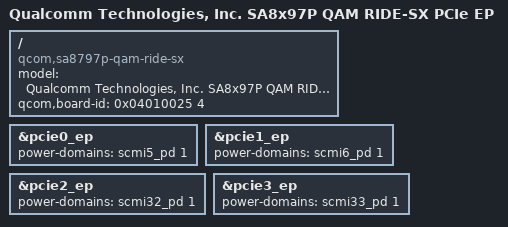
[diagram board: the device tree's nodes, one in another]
// SPDX-License-Identifier: BSD-3-Clause
/*
 * Copyright (c) Qualcomm Technologies, Inc. and/or its subsidiaries.
 */

/dts-v1/;

#include "sa8x97p.dtsi"
#include "sa8797p.dtsi"

/ {
	model = "Qualcomm Technologies, Inc. SA8x97P QAM RIDE-SX PCIe EP";
	compatible = "qcom,sa8797p-qam-ride-sx", "qcom,sa8797p-qam", "qcom,sa8797p";
	qcom,board-id = <0x04010025 4>;
};

&pcie0_ep {
	power-domains = <&scmi5_pd 1>;
	power-domain-names = "power";
	status = "okay";
};

&pcie1_ep {
	power-domains = <&scmi6_pd 1>;
	power-domain-names = "power";
};

&pcie2_ep {
	power-domains = <&scmi32_pd 1>;
	power-domain-names = "power";
};

&pcie3_ep {
	power-domains = <&scmi33_pd 1>;
	power-domain-names = "power";
};
